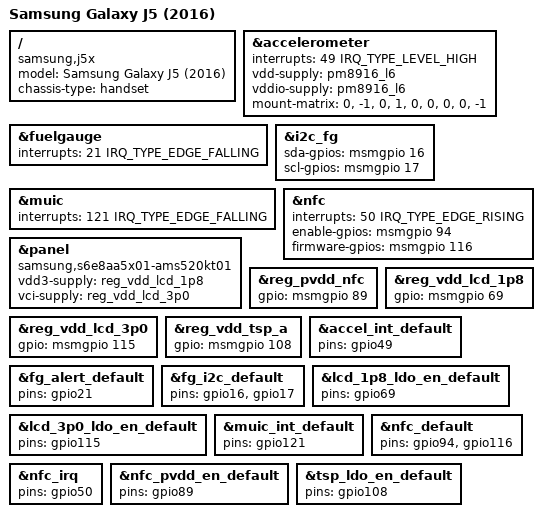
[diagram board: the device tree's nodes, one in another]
// SPDX-License-Identifier: GPL-2.0-only

/dts-v1/;

#include "msm8916-samsung-j5-common.dtsi"

/ {
	model = "Samsung Galaxy J5 (2016)";
	compatible = "samsung,j5x", "qcom,msm8916";
	chassis-type = "handset";
};

&accelerometer {
	interrupts = <49 IRQ_TYPE_LEVEL_HIGH>;

	vdd-supply = <&pm8916_l6>;
	vddio-supply = <&pm8916_l6>;

	mount-matrix = "0", "-1", "0",
		       "1", "0", "0",
		       "0", "0", "-1";
};

&fuelgauge {
	interrupts = <21 IRQ_TYPE_EDGE_FALLING>;
};

&i2c_fg {
	sda-gpios = <&msmgpio 16 (GPIO_ACTIVE_HIGH|GPIO_OPEN_DRAIN)>;
	scl-gpios = <&msmgpio 17 (GPIO_ACTIVE_HIGH|GPIO_OPEN_DRAIN)>;
};

&muic {
	interrupts = <121 IRQ_TYPE_EDGE_FALLING>;
};

&nfc {
	interrupts = <50 IRQ_TYPE_EDGE_RISING>;

	enable-gpios = <&msmgpio 94 GPIO_ACTIVE_HIGH>;
	firmware-gpios = <&msmgpio 116 GPIO_ACTIVE_HIGH>;
};

&panel {
	compatible = "samsung,s6e8aa5x01-ams520kt01";
	vdd3-supply = <&reg_vdd_lcd_1p8>;
	vci-supply = <&reg_vdd_lcd_3p0>;
};

&reg_pvdd_nfc {
	gpio = <&msmgpio 89 GPIO_ACTIVE_HIGH>;
};

&reg_vdd_lcd_1p8 {
	status = "okay";
	gpio = <&msmgpio 69 GPIO_ACTIVE_HIGH>;
};

&reg_vdd_lcd_3p0 {
	status = "okay";
	gpio = <&msmgpio 115 GPIO_ACTIVE_HIGH>;
};

&reg_vdd_tsp_a {
	status = "okay";
	gpio = <&msmgpio 108 GPIO_ACTIVE_HIGH>;
};

&accel_int_default {
	pins = "gpio49";
};

&fg_alert_default {
	pins = "gpio21";
};

&fg_i2c_default {
	pins = "gpio16", "gpio17";
};

&lcd_1p8_ldo_en_default {
	pins = "gpio69";
};

&lcd_3p0_ldo_en_default {
	pins = "gpio115";
};

&muic_int_default {
	pins = "gpio121";
};

&nfc_default {
	pins = "gpio94", "gpio116";
};

&nfc_irq {
	pins = "gpio50";
};

&nfc_pvdd_en_default {
	pins = "gpio89";
};

&tsp_ldo_en_default {
	pins = "gpio108";
};
